# Polarfire SoC register map
Vendor: Microchip; File version: 1.0
CPU: Microchip PolarFire SoC 1.0, little endian
Registers are 32-bit, read-write, reset 0x0 unless marked. A register's access mark holds for its fields unless they carry their own. Offsets are from the block's base; [hi:lo] are bit positions.

## MSTIMER_LO — MSTIMER_LO Controller
Base 0x20125000
Same registers: MSTIMER_HI 0x28125000
0x00 TIM1VALUE ro
  [31:0] TIM1VALUE — Current value of timer 1. This register is read only. Writing to this register has no effect.
0x04 TIM1LOADVAL
  [31:0] TIM1LOADVAL — Load value for timer 1. Write has no effect when timer is in 64 bit mode. Reading this register in 64 bit mode returns the reset value.When this register is written to, the value written is immediately loaded into the counter. This applies in both periodic and one-shot mode. If enabled, the counter will then continue counting down from this value. The value stored in this register is also used to reload the counter when the count reaches zero and the counter is operating in periodic mode. This register will be overwritten if the TIM1BGLOADVAL register is written to but the counter will not be updated with the new value in this case.TIM1LOADVAL always stores the value which will be loaded into the counter when it next reaches zero and periodic mode is selected.
0x08 TIM1BGLOADVAL
  [31:0] TIM1BGLOADVAL — Background load value for timer 1. Write has no effect when timer is in 64 bit mode.Reading this register in 64 bit mode returns the reset value. Background load value for timer 1. When this register is written to, the value written is loaded into the TIM1LOADVAL register without updating the counter itself. This allows a new load value to be put in place for the counter without interrupting the current count cycle.
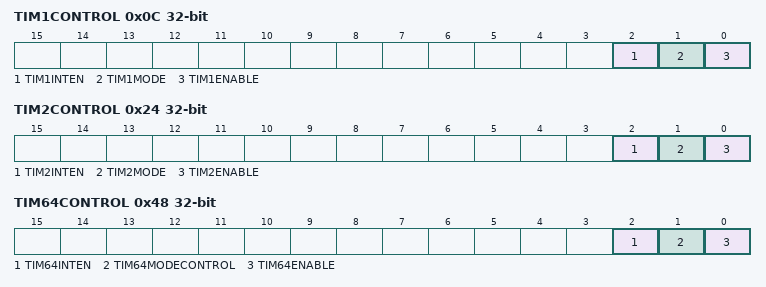
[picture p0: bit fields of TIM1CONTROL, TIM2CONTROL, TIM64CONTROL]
0x0C TIM1CONTROL
  [2] TIM1INTEN — Timer 1 interrupt enable bit. 0 = timer 1 interrupt disabled. 1 = timer 1 interrupt enabled.
  [1] TIM1MODE — This bit sets the operating mode for timer 1. 0= periodic mode. 1=one-shot mode.
  [0] TIM1ENABLE — Enable bit for timer 1: 0 = timer 1 disabled, i.e. counter decrements 1 = timer 1 enabled, i.e. counter value is static
0x10 TIM1RIS
  [0] TIM1RIS — Raw interrupt status bit for timer 1. This is bit is set when timer 1 reaches zero. Writing a '1' to this bit clears the bit. Writing '0' has no effect.
0x14 TIM1MIS ro
  [0] TIM1MIS — Masked interrupt status bit for timer 1. This read only bit is the logical AND of the TIM1RIS and TIM1INTEN bits. The TIMER1INT output from the timer will have the same value as this bit. Writing to this bit has no effect.
0x18 TIM2VALUE ro
  [31:0] TIM2VALUE — This read only register contains the current value of timer 2. Writing to this register has no effect.
0x1C TIM2LOADVAL
  [31:0] TIM2LOADVAL — Load value for timer 2.
0x20 TIM2BGLOADVAL
  [31:0] TIM2BGLOADVAL — Background load value for timer 2. When this register is written to, the value written is loaded into the TIM2LOADVAL register without updating the counter itself. This allows a new load value to be put in place for the counter without interrupting the current count cycle.
0x24 TIM2CONTROL
  [2] TIM2INTEN — Timer 2 interrupt enable bit. 0 = timer 2 interrupt disabled. 1 = timer 2 interrupt enabled.
  [1] TIM2MODE — This bit sets the operating mode for timer 2. 0=periodic mode, and 1= one-shot mode.
  [0] TIM2ENABLE — Enable bit for timer 2: 0 = timer 2 disabled, i.e. counter decrements, 1 = timer 2 enabled, i.e. counter value is static.
0x28 TIM2RIS
  [0] TIM2RIS — Raw interrupt status bit for timer 2. This is bit is set when timer 2 reaches zero. Writing a '1' to this bit clears the bit. Writing '0' has no effect.
0x2C TIM2MIS ro
  [0] TIM2MIS — Masked interrupt status bit for timer 2. This read only bit is the logical AND of the TIM2RIS and TIM2INTEN bits.The TIMER2INT output from the timer will have the same value as this bit. Writing to this bit has no effect.
0x30 TIM64VALUEU ro
  [31:0] TIM64VALUEU — This read only register contains the current value of the upper 32 bit word of the 64 bit timer. Reading this register returns the value of : TIM64TEMPVALU which is set when the lower 32 bits of the 64-bit timer is read.Writing to this register has no effect.
0x34 TIM64VALUEL ro
  [31:0] TIM64VALUEL — This read only register contains the current value of the lower 32 bit word of the 64 bit timer. Reading this register has the side effect of storing the upper 32 bits of the counter value in TIMTEMPVALU, which is accessed when the TIM64VALUEU register is read. Writing to this register has no effect.
0x38 TIM64LOADVALU
  [31:0] TIM64LOADVALU — Load value for upper 32 bits of 64 bit timer. When this register is written to, the value written is immediately loaded into a temporary register. The value in the temporary register is only written to the timer when the lower 32 bit word (TIM64LOADVALL) is written.
0x3C TIM64LOADVALL
  [31:0] TIM64LOADVALL — Load value for lower 32 bits of 64 bit timer. When this register is written to, the value written is immediately loaded into the lower 32 bits of the 64 bit counter along with the value in register TIM64LOADVALU. This applies in both periodic and one-shot mode. The value stored in this register is also used to reload the counter when the count reaches zero and the counter is operating in periodic mode. This register will be overwritten if the TIM64BGLOADVAL register is written to but the counter will not be updated with the new value in this case. TIM64LOADVALL always stores the lower 32 bits of the value which will be loaded into the counter when it next reaches zero and periodic mode is selected.
0x40 TIM64BGLOADVALU
  [31:0] TIM64BGLOADVALU — Background load value for upper 32 bits of 64 bit mode timer. This value only propagates the to the TIM64BGLOADVAL when the lower 32 bits is written.
0x44 TIM64BGLOADVALL
  [31:0] TIM64BGLOADVALL — Background load value for lower 32 bits of 64 bit mode timer. When this register is written to, the both the upper and lower words are written into the TIM64BGLOADVALL register without updating the counter itself. This allows a new load value to be put in place for the counter without interrupting the current count cycle.
0x48 TIM64CONTROL
  [2] TIM64INTEN — Timer 64 interrupt enable bit. 0 = timer 64 interrupt disabled. 1 = timer 2 interrupt enabled
  [1] TIM64MODECONTROL — This bit sets the operating mode for timer 64. 0=periodic mode and 1= one-shot mode.
  [0] TIM64ENABLE — Enable bit for 64 bit mode timer: 0 = timer 64 disabled, i.e. counter decrements 1 = timer 64 enabled, i.e. counter value is static
0x4C TIM64RIS
  [0] TIM64RIS — Raw interrupt status bit for 64 bit mode timer. This is bit is set when 64 bit mode timer reaches zero. Writing a '1' to this bit clears the bit. Writing '0' has no effect.
0x50 TIM64MIS ro
  [0] TIM64MIS — Masked interrupt status bit for 64 bit mode timer. This read only bit is the logical AND of the TIM64RIS and TIM64INTEN bits. The TIMER64INT output from the timer will have the same value as this bit. Writing to this bit has no effect.
0x54 TIM64MODE
  [0] TIM64MODE — Writing a 1 to this register forces the timers 1 and 2 to be used to implement a 64 bit mode timing. Writing a 0 forces the timers operate independently.
